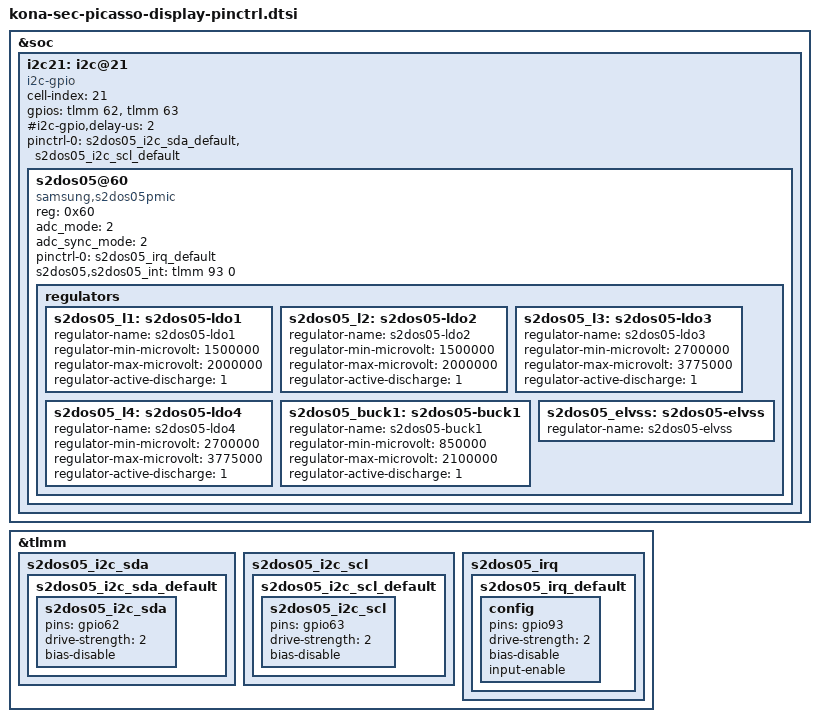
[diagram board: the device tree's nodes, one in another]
/* Copyright (c) 2019, The Linux Foundation. All rights reserved.
 *
 * This program is free software; you can redistribute it and/or modify
 * it under the terms of the GNU General Public License version 2 and
 * only version 2 as published by the Free Software Foundation.
 *
 * This program is distributed in the hope that it will be useful,
 * but WITHOUT ANY WARRANTY; without even the implied warranty of
 * MERCHANTABILITY or FITNESS FOR A PARTICULAR PURPOSE.  See the
 * GNU General Public License for more details.
 */

&soc {
	/* S2DOS05 Display PMIC */
	i2c21: i2c@21 {
		cell-index = <21>;
		compatible = "i2c-gpio";
		gpios = <&tlmm 62 0 /* sda */
			&tlmm 63 0 /* scl */
		>;
		#i2c-gpio,delay-us = <2>;
		#address-cells = <1>;
		#size-cells = <0>;

		pinctrl-names = "default";
		pinctrl-0 = <&s2dos05_i2c_sda_default &s2dos05_i2c_scl_default>;

		s2dos05@60 {
			compatible = "samsung,s2dos05pmic";
			reg = <0x60>;
			adc_mode = <2>; /* 0 : disable, 1 : current meter, 2 : power meter */
			adc_sync_mode = <2>; /* 1 : sync mode, 2 : async mode */

			pinctrl-names = "default";
			pinctrl-0 = <&s2dos05_irq_default>;
			s2dos05,s2dos05_int = <&tlmm 93 0>;

			regulators {
				s2dos05_l1: s2dos05-ldo1 {
					regulator-name = "s2dos05-ldo1";
					regulator-min-microvolt = <1500000>;
					regulator-max-microvolt = <2000000>;
					regulator-active-discharge = <1>;
				};

				s2dos05_l2: s2dos05-ldo2 {
					regulator-name = "s2dos05-ldo2";
					regulator-min-microvolt = <1500000>;
					regulator-max-microvolt = <2000000>;
					regulator-active-discharge = <1>;
				};

				s2dos05_l3: s2dos05-ldo3 {
					regulator-name = "s2dos05-ldo3";
					regulator-min-microvolt = <2700000>;
					regulator-max-microvolt = <3775000>;
					regulator-active-discharge = <1>;
				};

				s2dos05_l4: s2dos05-ldo4 {
					regulator-name = "s2dos05-ldo4";
					regulator-min-microvolt = <2700000>;
					regulator-max-microvolt = <3775000>;
					regulator-active-discharge = <1>;
				};

				s2dos05_buck1: s2dos05-buck1 {
					regulator-name = "s2dos05-buck1";
					regulator-min-microvolt = <850000>;
					regulator-max-microvolt = <2100000>;
					regulator-active-discharge = <1>;
				};

				s2dos05_elvss: s2dos05-elvss {
					regulator-name = "s2dos05-elvss";
				};
			};
		};
	};
};

&tlmm {
	s2dos05_i2c_sda {
		s2dos05_i2c_sda_default: s2dos05_i2c_sda_default {
			s2dos05_i2c_sda {
				pins = "gpio62";
				drive-strength = <2>;
				bias-disable;
			};
		};
	};
	s2dos05_i2c_scl {
		s2dos05_i2c_scl_default: s2dos05_i2c_scl_default {
			s2dos05_i2c_scl {
				pins = "gpio63";
				drive-strength = <2>;
				bias-disable;
			};
		};
	};
	s2dos05_irq {
		s2dos05_irq_default: s2dos05_irq_default {
			config {
				pins = "gpio93";
				drive-strength = <2>;
				bias-disable;
				input-enable;
			};
		};
	};
};
